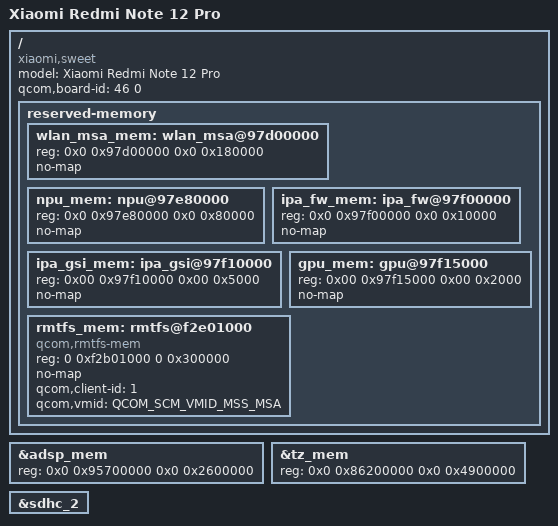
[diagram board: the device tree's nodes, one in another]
// SPDX-License-Identifier: BSD-3-Clause

 /dts-v1/;

#include "sm7150-xiaomi-common.dtsi"

/delete-node/ &wlan_msa_mem;
/delete-node/ &npu_mem;
/delete-node/ &ipa_fw_mem;
/delete-node/ &ipa_gsi_mem;
/delete-node/ &gpu_mem;

&adsp_mem {
	reg = <0x0 0x95700000 0x0 0x2600000>;
};

&tz_mem {
	reg = <0x0 0x86200000 0x0 0x4900000>;
};

/ {
 	model = "Xiaomi Redmi Note 12 Pro";
 	compatible = "xiaomi,sweet", "qcom,sm7150"; /* sweet_k6a actually uses the sweet codename */

	qcom,board-id = <46 0>;

	reserved-memory {
		wlan_msa_mem: wlan_msa@97d00000 {
			reg = <0x0 0x97d00000 0x0 0x180000>;
			no-map;
		};

		npu_mem: npu@97e80000 {
			reg = <0x0 0x97e80000 0x0 0x80000>;
			no-map;
		};

		ipa_fw_mem: ipa_fw@97f00000 {
			reg = <0x0 0x97f00000 0x0 0x10000>;
			no-map;
		};

		ipa_gsi_mem: ipa_gsi@97f10000 {
			reg = <0x00 0x97f10000 0x00 0x5000>;
			no-map;
		};

		gpu_mem: gpu@97f15000 {
			reg = <0x00 0x97f15000 0x00 0x2000>;
			no-map;
		};

		rmtfs_mem: rmtfs@f2e01000 { /* recheck in twrp */
			compatible = "qcom,rmtfs-mem";
			reg = <0 0xf2b01000 0 0x300000>;
			no-map;

			qcom,client-id = <1>;
			qcom,vmid = <QCOM_SCM_VMID_MSS_MSA>;
		};

	};
};

&sdhc_2 {
	status = "okay";
};
